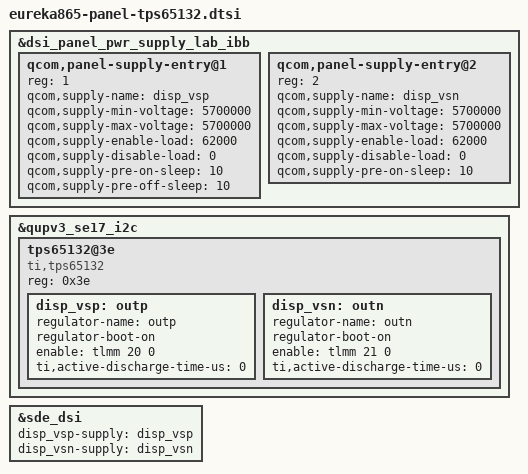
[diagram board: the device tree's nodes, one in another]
// SPDX-License-Identifier: GPL-2.0

&dsi_panel_pwr_supply_lab_ibb {
	qcom,panel-supply-entry@1 {
		reg = <1>;
		qcom,supply-name = "disp_vsp";
		qcom,supply-min-voltage = <5700000>;
		qcom,supply-max-voltage = <5700000>;
		qcom,supply-enable-load = <62000>;
		qcom,supply-disable-load = <0>;
		qcom,supply-pre-on-sleep = <10>;
		qcom,supply-pre-off-sleep = <10>;
	};

	qcom,panel-supply-entry@2 {
		reg = <2>;
		qcom,supply-name = "disp_vsn";
		qcom,supply-min-voltage = <5700000>;
		qcom,supply-max-voltage = <5700000>;
		qcom,supply-enable-load = <62000>;
		qcom,supply-disable-load = <0>;
		qcom,supply-pre-on-sleep = <10>;
	};
};

&qupv3_se17_i2c {
	tps65132@3e {
		compatible = "ti,tps65132";
		reg = <0x3e>;

		disp_vsp: outp {
			regulator-name = "outp";
			regulator-boot-on;
			enable = <&tlmm 20 0>;
			ti,active-discharge-time-us = <0>;
		};

		disp_vsn: outn {
			regulator-name = "outn";
			regulator-boot-on;
			enable = <&tlmm 21 0>;
			ti,active-discharge-time-us = <0>;
		};
	};
};

&sde_dsi {
	disp_vsp-supply = <&disp_vsp>;
	disp_vsn-supply = <&disp_vsn>;
};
